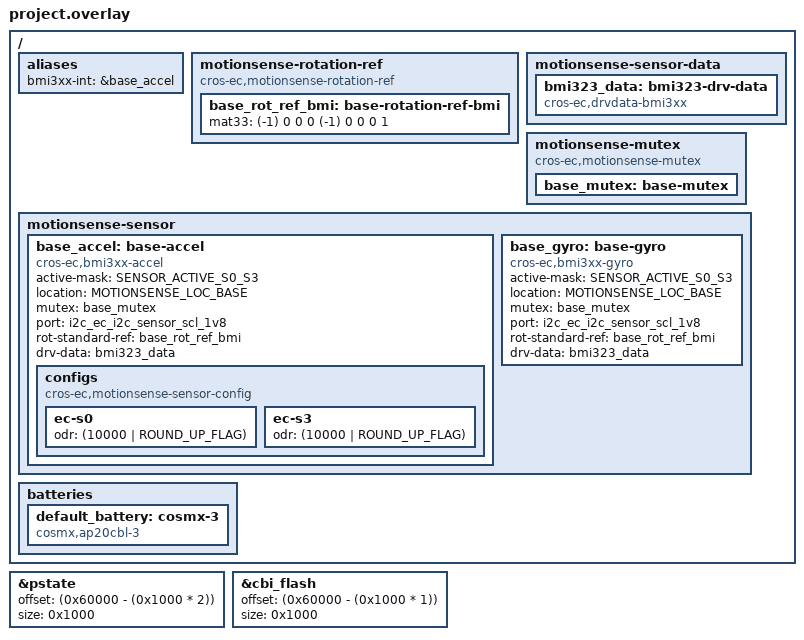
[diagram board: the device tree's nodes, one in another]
/* Copyright 2023 The ChromiumOS Authors
 * Use of this source code is governed by a BSD-style license that can be
 * found in the LICENSE file.
 */

#include <cros/cbi_flash.dtsi>
#include <dt-bindings/motionsense/utils.h>

#include "../arbitrage.dtsi"
#include "../common.dtsi"
#include "../usbc.dtsi"
#include "../generated.dtsi"
#include "../interrupts.dtsi"
#include "../motionsense.dtsi"
#include "../keyboard.dtsi"
#include "../overlay.dtsi"
#include "../power_signal.dtsi"

/ {
	aliases {
		bmi3xx-int = &base_accel;
	};

	/* Rotation matrix used by drivers. */
	motionsense-rotation-ref {
		compatible = "cros-ec,motionsense-rotation-ref";
		base_rot_ref_bmi: base-rotation-ref-bmi {
			mat33 = <(-1) 0 0
				 0 (-1) 0
				 0 0 1>;
		};
	};

	motionsense-sensor-data {
		bmi323_data: bmi323-drv-data {
			compatible = "cros-ec,drvdata-bmi3xx";
			status = "okay";
		};
	};
	/*
	 * Declare mutexes used by sensor drivers.
	 * A mutex node is used to create an instance of mutex_t.
	 * A mutex node is referenced by a sensor node if the
	 * corresponding sensor driver needs to use the
	 * instance of the mutex.
	 */
	motionsense-mutex {
		compatible = "cros-ec,motionsense-mutex";
		base_mutex: base-mutex {
		};

	};

	motionsense-sensor {
		base_accel: base-accel {
			compatible = "cros-ec,bmi3xx-accel";
			status = "okay";

			active-mask = "SENSOR_ACTIVE_S0_S3";
			location = "MOTIONSENSE_LOC_BASE";
			mutex = <&base_mutex>;
			port = <&i2c_ec_i2c_sensor_scl_1v8>;
			rot-standard-ref = <&base_rot_ref_bmi>;
			drv-data = <&bmi323_data>;
			configs {
				compatible =
					"cros-ec,motionsense-sensor-config";
				ec-s0 {
					odr = <(10000 | ROUND_UP_FLAG)>;
				};
				ec-s3 {
					odr = <(10000 | ROUND_UP_FLAG)>;
				};
			};
		};
		base_gyro: base-gyro {
			compatible = "cros-ec,bmi3xx-gyro";
			status = "okay";

			active-mask = "SENSOR_ACTIVE_S0_S3";
			location = "MOTIONSENSE_LOC_BASE";
			mutex = <&base_mutex>;
			port = <&i2c_ec_i2c_sensor_scl_1v8>;
			rot-standard-ref = <&base_rot_ref_bmi>;
			drv-data = <&bmi323_data>;
		};
	};

	batteries {
		default_battery: cosmx-3 {
			compatible = "cosmx,ap20cbl-3", "battery-smart";
		};
	};
};

/*
 * When CBI in flash is enabled, setup RO flash layout as follows:
 *   RO binary:    0x00000:0x5DFFF
 *   PSTATE block: 0x5E000:0x5EFFF
 *   CBI flash:    0x5F000:0x5FFFF
 */
&pstate {
	offset = <(0x60000 - (0x1000 * 2))>;
	size = <0x1000>;
};

&cbi_flash {
	offset = <(0x60000 - (0x1000 * 1))>;
	size = <0x1000>;
};
